# STM32MP23_CM33 register map
File version: 1.2
CPU: CM33 r0p1, little endian, MPU, FPU, vendor SysTick, 8 interrupt priority bits
Registers are 32-bit, read-write, reset 0x0 unless marked. A register's access mark holds for its fields unless they carry their own. Offsets are from the block's base; [hi:lo] are bit positions.

## ADCC12 — ADCC12 register block
Base 0x404E0300
Same registers: ADCC12_S 0x504E0300
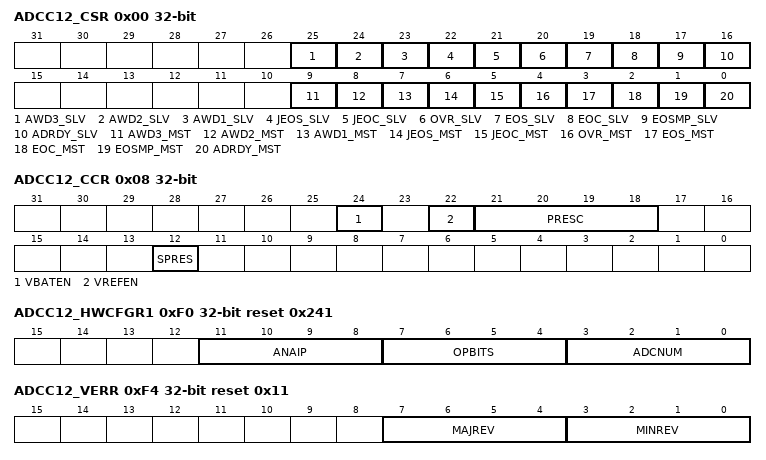
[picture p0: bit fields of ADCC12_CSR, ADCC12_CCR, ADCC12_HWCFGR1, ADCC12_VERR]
0x00 ADCC12_CSR ro — ADC12 common status register
  [25] AWD3_SLV — Analog watchdog 3 flag of the slave ADC This bit is a copy of the AWD3 bit in the corresponding ADC_ISR register.
  [24] AWD2_SLV — Analog watchdog 2 flag of the slave ADC This bit is a copy of the AWD2 bit in the corresponding ADC_ISR register.
  [23] AWD1_SLV — Analog watchdog 1 flag of the slave ADC This bit is a copy of the AWD1 bit in the corresponding ADC_ISR register.
  [22] JEOS_SLV — End of injected sequence flag of the slave ADC This bit is a copy of the JEOS bit in the corresponding ADC_ISR register.
  [21] JEOC_SLV — End of injected conversion flag of the slave ADC This bit is a copy of the JEOC bit in the corresponding ADC_ISR register.
  [20] OVR_SLV — Overrun flag of the slave ADC This bit is a copy of the OVR bit in the corresponding ADC_ISR register.
  [19] EOS_SLV — End of regular sequence flag of the slave ADC. This bit is a copy of the EOS bit in the corresponding ADC_ISR register.
  [18] EOC_SLV — End of regular conversion of the slave ADC This bit is a copy of the EOC bit in the corresponding ADC_ISR register.
  [17] EOSMP_SLV — End of sampling phase flag of the slave ADC This bit is a copy of the EOSMP2 bit in the corresponding ADC_ISR register.
  [16] ADRDY_SLV — Slave ADC ready This bit is a copy of the ADRDY bit in the corresponding ADC_ISR register.
  [9] AWD3_MST — Analog watchdog 3 flag of the master ADC This bit is a copy of the AWD3 bit in the corresponding ADC_ISR register.
  [8] AWD2_MST — Analog watchdog 2 flag of the master ADC This bit is a copy of the AWD2 bit in the corresponding ADC_ISR register.
  [7] AWD1_MST — Analog watchdog 1 flag of the master ADC This bit is a copy of the AWD1 bit in the corresponding ADC_ISR register.
  [6] JEOS_MST — End of injected sequence flag of the master ADC This bit is a copy of the JEOS bit in the corresponding ADC_ISR register.
  [5] JEOC_MST — End of injected conversion flag of the master ADC This bit is a copy of the JEOC bit in the corresponding ADC_ISR register.
  [4] OVR_MST — Overrun flag of the master ADC This bit is a copy of the OVR bit in the corresponding ADC_ISR register.
  [3] EOS_MST — End of regular sequence flag of the master ADC This bit is a copy of the EOS bit in the corresponding ADC_ISR register.
  [2] EOC_MST — End of regular conversion of the master ADC This bit is a copy of the EOC bit in the corresponding ADC_ISR register.
  [1] EOSMP_MST — End of Sampling phase flag of the master ADC This bit is a copy of the EOSMP bit in the corresponding ADC_ISR register.
  [0] ADRDY_MST — Master ADC ready This bit is a copy of the ADRDY bit in the corresponding ADC_ISR register.
0x08 ADCC12_CCR — ADC12 common control register
  [24] VBATEN — VBAT enable This bit is set and cleared by software to enable/disable the VsubBAT/sub channel. Note: VsubBAT /subis not available on all ADC instances. Refer to Section41.4.4: ADC connectivity for details.
    0=VsubBAT/sub channel disabled; 1=VsubBAT/sub channel enabled
  [22] VREFEN — VsubREFINT/sub enable This bit is set and cleared by software to enable/disable the VsubREFINT/sub channel. Note: VsubREFINT/sub is not available on all ADC instances. Refer to Section41.4.4: ADC connectivity for details.
    0=VsubREFINT/sub channel disabled; 1=VsubREFINT/sub channel enabled
  [21:18] PRESC — ADC prescaler These bits are set and cleared by software to select the frequency of the clock to the ADC. The clock is common for all the ADCs. Other: reserved, must not be used Note: The software is allowed to write these bits only when the ADC is disabled (ADCAL=0, JADSTART=0, ADSTART=0, ADSTP=0, ADDIS=0 and ADEN=0).
    0=input ADC clock not divided; 1=input ADC clock divided by 2; 2=input ADC clock divided by 4; 3=input ADC clock divided by 6; 4=input ADC clock divided by 8; 5=input ADC clock divided by 10; 6=input ADC clock divided by 12; 7=input ADC clock divided by 16; 8=input ADC clock divided by 32; 9=input ADC clock divided by 64; 10=input ADC clock divided by 128; 11=input ADC clock divided by 256
  [12] SPRES — Single prescaler mode This bit is set and cleared by software to enable/disable the single prescaler mode. Note: The software is allowed to write this bit only when both ADC1 and ADC2 are disabled.
    0=Default prescaler configuration (each ADC might have own prescaler); 1=One prescaler configuration (both ADCs are forced to use one prescaler)
0xF0 ADCC12_HWCFGR1 ro reset 0x241 — ADC12 hardware configuration register
  [11:8] ANAIP — Analog IP compatibility
    1=ADC12M40; 2=ADC12FF16; 3=ADC12P18; 4=ADC12M40SE
  [7:4] OPBITS — Number of option bits
    0=No option register implemented; 1=1 option bit implemented in the ADC option register (ADC_OR) at address offset 0x0D0; 2=2 option bits implemented in the ADC option register (ADC_OR) at address offset 0x0D0
  [3:0] ADCNUM — Number of ADCs implemented
    1=One ADC instance implemented; 2=Two ADC instances implemented; 3=Three ADCs instances implemented
0xF4 ADCC12_VERR ro reset 0x11 — ADC12 version register
  [7:4] MAJREV — Major revision These bits returns the ADC IP major revision
    1=Major revision=1.X; 2=Major revision=2.X
  [3:0] MINREV — Minor revision These bits returns the ADC IP minor revision
    0=Minor revision = X.0; 1=Minor revision = X.1
0xF8 ADCC12_IPIDR ro reset 0x110008 — ADC12 identification register
  [31:0] ID — Peripheral identifier These bits returns the ADC identifier. ID[31:0]=0x00110008: c7amba_aditf6
0xFC ADCC12_SIDR ro reset 0xA3C5DD01 — ADC12 size identification register
  [31:0] SID — Size Identification SID[31:8]: fixed code that characterizes the ADCx_SIDR register. This field is always read at 0xA3C5DD. SID[7:0]: read-only numeric field that returns the address offset (in Kbytes) of the identification registers from the IP base address:
    1=1Kbytes address offset; 2=2Kbytes address offset; 4=4Kbytes address offset; 8=8Kbytes address offset

## Notices in the file
Copyright (c) 2025 STMicroelectronics.
SPDX-License-Identifier: Apache-2.0
Licensed under the Apache License, Version 2.0 (the "License");
you may not use this file except in compliance with the License.
You may obtain a copy of the License at
http://www.apache.org/licenses/LICENSE-2.0
Unless required by applicable law or agreed to in writing, software
distributed under the License is distributed on an "AS IS" BASIS,
WITHOUT WARRANTIES OR CONDITIONS OF ANY KIND, either express or implied.
See the License for the specific language governing permissions and
limitations under the License.
